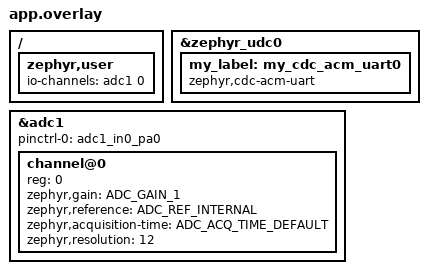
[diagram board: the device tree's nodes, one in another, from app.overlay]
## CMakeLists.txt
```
cmake_minimum_required(VERSION 3.20)
find_package(Zephyr REQUIRED HINTS $ENV{ZEPHYR_BASE})
project(ZephyrPrac)
target_sources(app PRIVATE src/main.c)
```

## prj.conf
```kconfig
CONFIG_USB_DEVICE_STACK=y
CONFIG_SERIAL=y
CONFIG_USB_CDC_ACM=y
CONFIG_DEBUG=y
CONFIG_ADC=y
CONFIG_ADC_STM32=y
CONFIG_LOG_MODE_IMMEDIATE=y
CONFIG_LOG=y
```

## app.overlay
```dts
&zephyr_udc0 {
    my_label: my_cdc_acm_uart0 {
        compatible = "zephyr,cdc-acm-uart";
    };
};

/ {
    zephyr,user {
        io-channels = <&adc1 0>;
    };
};

&adc1 {
    status = "okay";
    pinctrl-0 = <&adc1_in0_pa0>;
    pinctrl-names = "default";
    #address-cells = <1>;
    #size-cells = <0>;

    channel@0 {
        reg = <0>;
        zephyr,gain = "ADC_GAIN_1";
        zephyr,reference = "ADC_REF_INTERNAL";
        zephyr,acquisition-time = <ADC_ACQ_TIME_DEFAULT>;
        zephyr,resolution = <12>;
    };
};
```

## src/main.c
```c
#include <stdint.h>
#include <string.h>
#include <zephyr/device.h>
#include <zephyr/drivers/adc.h>
#include <zephyr/drivers/uart.h>
#include <zephyr/kernel.h>
#include <zephyr/logging/log.h>
#include <zephyr/usb/usb_device.h>

LOG_MODULE_REGISTER(main, LOG_LEVEL_INF);

int main(void) {
  const struct device *usb_dev = DEVICE_DT_GET(DT_NODELABEL(my_label));
  const struct adc_dt_spec adc1 = ADC_DT_SPEC_GET(DT_PATH(zephyr_user));

  int err = 0;
  uint16_t buff = 0;

  if (!adc_is_ready_dt(&adc1)) {
    LOG_ERR("e1");
    return 1;
  }

  err = adc_channel_setup_dt(&adc1);
  if (err < 0) {
    LOG_ERR("e2");
    return 2;
  }

  struct adc_sequence sequence = {.buffer = &buff, .buffer_size = sizeof(buff)};
  //
  err = adc_sequence_init_dt(&adc1, &sequence);

  char data[] = "hello\r\n";
  int len = strlen(data);

  usb_enable(NULL);
  k_msleep(1000);

  while (1) {
    err = adc_read(adc1.dev, &sequence);
    uart_fifo_fill(usb_dev, (const int8_t *)&buff, 2);
    // uart_fifo_fill(usb_dev, data, len);
    k_usleep(1);
  }
}
```
